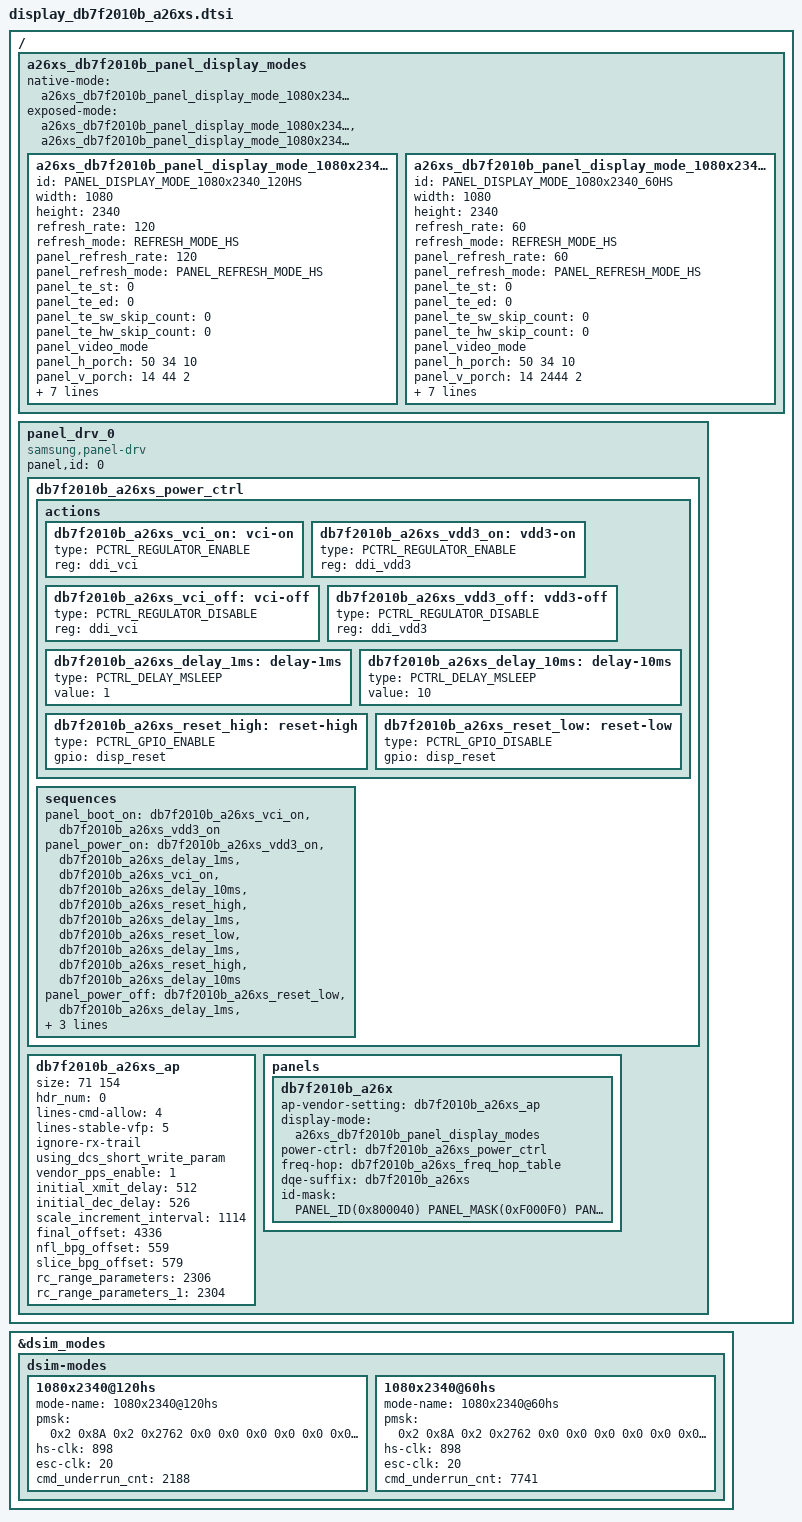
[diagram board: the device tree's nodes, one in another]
/*
 * Samsung Exynos SoC series Panel driver
 *
 * Copyright (c) 2020 Samsung Electronics Co., Ltd
 *
 * This program is free software; you can redistribute it and/or modify
 * it under the terms of the GNU General Public License version 2 as
 * published by the Free Software Foundation.
 */

#include <dt-bindings/display/panel-display.h>
#include "../display_db7f2010b_a26xs_adaptive_mipi.dtsi"

&dsim_modes {
	dsim-modes {
		1080x2340@120hs {
			mode-name = "1080x2340@120hs";
			pmsk = <
				0x2 0x8A 0x2 0x2762 /* p m s k */
				0x0 0x0 0x0 0x0
				0x0 0x0 0x0 0x0
				0x0 0x0
				>;
			hs-clk = <898>;
			esc-clk = <20>;
			cmd_underrun_cnt = <2188>;
		};
		1080x2340@60hs {
			mode-name = "1080x2340@60hs";
			pmsk = <
				0x2 0x8A 0x2 0x2762 /* p m s k */
				0x0 0x0 0x0 0x0
				0x0 0x0 0x0 0x0
				0x0 0x0
				>;
			hs-clk = <898>;
			esc-clk = <20>;
			cmd_underrun_cnt = <7741>;
		};
	};
};

/ {
	fragment@panel_display_mode {
		target-path = "/";
		__overlay__ {
			a26xs_db7f2010b_panel_display_modes:
			a26xs_db7f2010b_panel_display_modes {
				native-mode = <&a26xs_db7f2010b_panel_display_mode_1080x2340_120hs>;
				exposed-mode = <
					&a26xs_db7f2010b_panel_display_mode_1080x2340_120hs
					&a26xs_db7f2010b_panel_display_mode_1080x2340_60hs
				>;

				/* fhd */
				a26xs_db7f2010b_panel_display_mode_1080x2340_120hs:
				a26xs_db7f2010b_panel_display_mode_1080x2340_120hs {
					id = PANEL_DISPLAY_MODE_1080x2340_120HS;
					width = <1080>;
					height = <2340>;
					/* timing parameters */
					refresh_rate = <120>;			/* logical refresh rate */
					refresh_mode = <REFRESH_MODE_HS>;
					panel_refresh_rate = <120>;		/* panel internal refresh rate */
					panel_refresh_mode = <PANEL_REFRESH_MODE_HS>;
					panel_te_st = <0>;				/* te rising */
					panel_te_ed = <0>;				/* te falling */
					panel_te_sw_skip_count = <0>;	/* s/w te modulation */
					panel_te_hw_skip_count = <0>;	/* h/w te modulation */

					panel_video_mode;
					panel_h_porch = <50 34 10>;
					panel_v_porch = <14 44 2>;
					/* dsc parameters */
					dsc_en = <1>;			/* 0:Disable, 1:Enable */
					dsc_cnt = <1>;			/* used DSC count */
					dsc_slice_num = <2>;	/* count of dsc slice */
					dsc_slice_w = <540>;	/* width of dsc slice */
					dsc_slice_h = <45>;	/* height of dsc slice */

					/* dsi parameters */
					cmd_lp_ref = <1761>;

					/*qos parameters */
					disp_qos_fps = <120>;
				};

				a26xs_db7f2010b_panel_display_mode_1080x2340_60hs:
				a26xs_db7f2010b_panel_display_mode_1080x2340_60hs {
					id = PANEL_DISPLAY_MODE_1080x2340_60HS;
					width = <1080>;
					height = <2340>;
					/* timing parameters */
					refresh_rate = <60>;			/* logical refresh rate */
					refresh_mode = <REFRESH_MODE_HS>;
					panel_refresh_rate = <60>;		/* panel internal refresh rate */
					panel_refresh_mode = <PANEL_REFRESH_MODE_HS>;
					panel_te_st = <0>;				/* te rising */
					panel_te_ed = <0>;				/* te falling */
					panel_te_sw_skip_count = <0>;	/* s/w te modulation */
					panel_te_hw_skip_count = <0>;	/* h/w te modulation */

					panel_video_mode;
					panel_h_porch = <50 34 10>;
					panel_v_porch = <14 2444 2>;

					/* dsc parameters */
					dsc_en = <1>;			/* 0:Disable, 1:Enable */
					dsc_cnt = <1>;			/* used DSC count */
					dsc_slice_num = <2>;	/* count of dsc slice */
					dsc_slice_w = <540>;	/* width of dsc slice */
					dsc_slice_h = <45>;	/* height of dsc slice */

					/* dsi parameters */
					cmd_lp_ref = <7474>;

					/*qos parameters */
					disp_qos_fps = <120>;
				};
			};
		};
	};
};


/ {
	fragment@panel_drv {
		target-path = "/";
		__overlay__ {
			panel_drv_0: panel_drv_0 {
				status = "okay";
				compatible = "samsung,panel-drv";
				panel,id = <0>;

				db7f2010b_a26xs_power_ctrl:
				db7f2010b_a26xs_power_ctrl {
					actions {
						db7f2010b_a26xs_vci_on: vci-on {
							type = <PCTRL_REGULATOR_ENABLE>;
							reg = <&ddi_vci>;
						};
						db7f2010b_a26xs_vdd3_on: vdd3-on {
							type = <PCTRL_REGULATOR_ENABLE>;
							reg = <&ddi_vdd3>;
						};
						db7f2010b_a26xs_vci_off: vci-off {
							type = <PCTRL_REGULATOR_DISABLE>;
							reg = <&ddi_vci>;
						};
						db7f2010b_a26xs_vdd3_off: vdd3-off {
							type = <PCTRL_REGULATOR_DISABLE>;
							reg = <&ddi_vdd3>;
						};
						db7f2010b_a26xs_delay_1ms: delay-1ms {
							type = <PCTRL_DELAY_MSLEEP>;
							value = <1>;
						};
						db7f2010b_a26xs_delay_10ms: delay-10ms {
							type = <PCTRL_DELAY_MSLEEP>;
							value = <10>;
						};
						db7f2010b_a26xs_reset_high: reset-high {
							type = <PCTRL_GPIO_ENABLE>;
							gpio = <&disp_reset>;
						};
						db7f2010b_a26xs_reset_low: reset-low {
							type = <PCTRL_GPIO_DISABLE>;
							gpio = <&disp_reset>;
						};
					};
					sequences {
						panel_boot_on = <&db7f2010b_a26xs_vci_on &db7f2010b_a26xs_vdd3_on>;
						panel_power_on = <
								&db7f2010b_a26xs_vdd3_on &db7f2010b_a26xs_delay_1ms &db7f2010b_a26xs_vci_on &db7f2010b_a26xs_delay_10ms
								&db7f2010b_a26xs_reset_high &db7f2010b_a26xs_delay_1ms
								&db7f2010b_a26xs_reset_low &db7f2010b_a26xs_delay_1ms
								&db7f2010b_a26xs_reset_high &db7f2010b_a26xs_delay_10ms
						>;
						panel_power_off = <&db7f2010b_a26xs_reset_low &db7f2010b_a26xs_delay_1ms &db7f2010b_a26xs_vci_off &db7f2010b_a26xs_delay_10ms &db7f2010b_a26xs_vdd3_off>;
					};
				};

				db7f2010b_a26xs_ap:db7f2010b_a26xs_ap {
					/* S.LSI (s5e8825 not add "SLSI" prefix) */
					size = <71 154>;	/* 70.848 mm x 153.504 mm */
					hdr_num = <0>;
					lines-cmd-allow = <4>;
					lines-stable-vfp = <5>;
					ignore-rx-trail;
					using_dcs_short_write_param;

					/* DSC PPS vender setting (optional) */
					vendor_pps_enable = <1>;
					initial_xmit_delay = <512>;
					initial_dec_delay = <526>;
					scale_increment_interval = <1114>;
					final_offset = <4336>;
					nfl_bpg_offset = <559>;
					slice_bpg_offset = <579>;
					rc_range_parameters = <2306>;
					rc_range_parameters_1 = <2304>;
				};

				panels {
					db7f2010b_a26x: db7f2010b_a26x {
						ap-vendor-setting = <&db7f2010b_a26xs_ap>;
						display-mode = <&a26xs_db7f2010b_panel_display_modes>;
						power-ctrl = <&db7f2010b_a26xs_power_ctrl>;
						freq-hop = <&db7f2010b_a26xs_freq_hop_table>;
						dqe-suffix = "db7f2010b_a26xs";
						id-mask = <
							PANEL_ID(0x800040) PANEL_MASK(0xF000F0)
							PANEL_ID(0x000000) PANEL_MASK(0x000000)
						>;
					};
				};
			};
		};
	};
};


